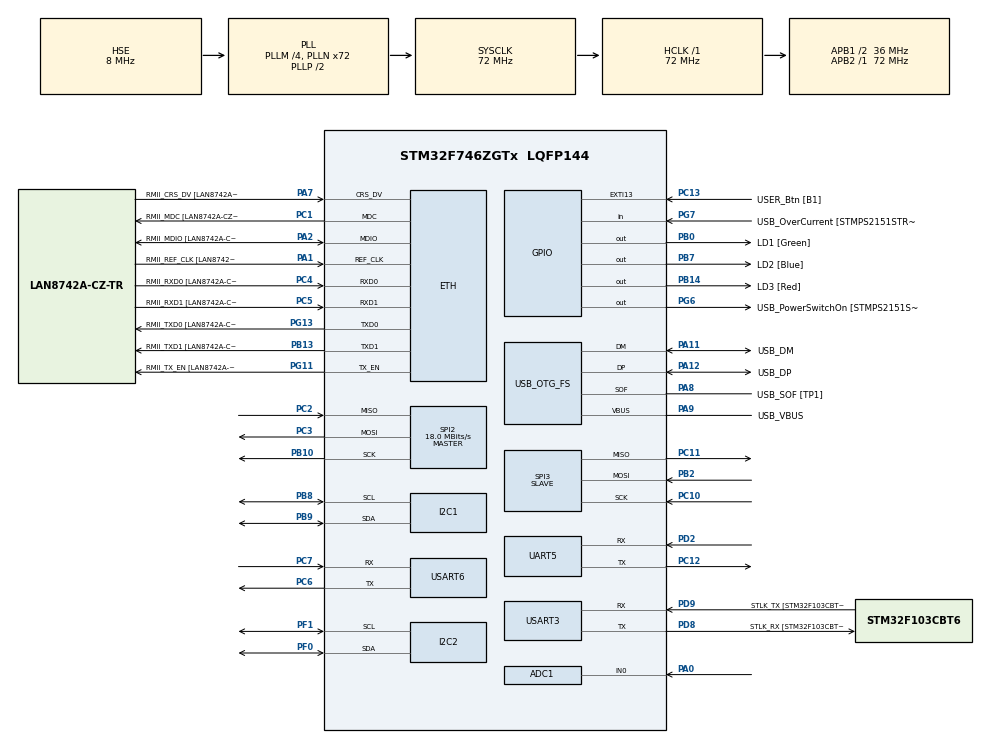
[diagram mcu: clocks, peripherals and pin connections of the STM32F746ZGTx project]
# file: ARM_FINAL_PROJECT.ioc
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ADC1.Channel-0\#ChannelRegularConversion=ADC_CHANNEL_0
ADC1.NbrOfConversionFlag=1
ADC1.Rank-0\#ChannelRegularConversion=1
ADC1.SamplingTime-0\#ChannelRegularConversion=ADC_SAMPLETIME_3CYCLES
ADC1.master=1
ETH.MediaInterface=HAL_ETH_RMII_MODE
ETH.PHY_Name=LAN8742A_PHY_ADDRESS
ETH.PHY_Value=0
ETH.PhyAddress=0
I2C1.Timing=0x00808CD2
I2C2.OwnAddress=22
I2C2.Timing=0x00808CD2
LWIP.BSP.number=1
LWIP.GATEWAY_ADDRESS=192.168.000.001
LWIP.IP_ADDRESS=192.168.000.123
LWIP.LWIP_DHCP=0
LWIP.MEM_SIZE=10*1024
LWIP.NETMASK_ADDRESS=255.255.255.000
LWIP.Version=v2.1.2_Cube
LWIP0.BSP.STBoard=false
LWIP0.BSP.api=BSP_COMPONENT_DRIVER
LWIP0.BSP.component=LAN8742
LWIP0.BSP.instance=LAN8742
LWIP0.BSP.name=Driver_PHY
LWIP0.BSP.semaphore=S_LAN8742
LWIP0.BSP.solution=LAN8742
Mcu.Family=STM32F7
Mcu.Name=STM32F746ZGTx
Mcu.Package=LQFP144
NVIC.ADC_IRQn=true\:0\:0\:false\:false\:true\:true\:true\:true
NVIC.ETH_IRQn=true\:0\:0\:false\:false\:true\:true\:true\:true
NVIC.I2C1_EV_IRQn=true\:0\:0\:false\:false\:true\:true\:true\:true
NVIC.I2C2_EV_IRQn=true\:0\:0\:false\:false\:true\:true\:true\:true
NVIC.PriorityGroup=NVIC_PRIORITYGROUP_4
NVIC.RTC_WKUP_IRQn=true\:0\:0\:false\:false\:true\:true\:true\:true
NVIC.SPI2_IRQn=true\:0\:0\:false\:false\:true\:true\:true\:true
NVIC.SPI3_IRQn=true\:0\:0\:false\:false\:true\:true\:true\:true
NVIC.TIM3_IRQn=true\:0\:0\:false\:false\:true\:true\:true\:true
NVIC.USART6_IRQn=true\:0\:0\:false\:false\:true\:true\:true\:true
PA0/WKUP.Signal=ADCx_IN0
PA1.GPIO_Label=RMII_REF_CLK [LAN8742A-CZ-TR_REFCLK0]
PA1.Mode=RMII
PA1.Signal=ETH_REF_CLK
PA10.GPIO_Label=USB_ID
PA10.Signal=USB_OTG_FS_ID
PA11.GPIO_Label=USB_DM
PA11.Mode=Device_Only
PA11.Signal=USB_OTG_FS_DM
PA12.GPIO_Label=USB_DP
PA12.Mode=Device_Only
PA12.Signal=USB_OTG_FS_DP
PA13.GPIO_Label=TMS
PA13.Mode=Serial_Wire
PA13.Signal=SYS_JTMS-SWDIO
PA14.GPIO_Label=TCK
PA14.Mode=Serial_Wire
PA14.Signal=SYS_JTCK-SWCLK
PA2.GPIO_Label=RMII_MDIO [LAN8742A-CZ-TR_MDIO]
PA2.Mode=RMII
PA2.Signal=ETH_MDIO
PA7.GPIO_Label=RMII_CRS_DV [LAN8742A-CZ-TR_CRS_DV]
PA7.Mode=RMII
PA7.Signal=ETH_CRS_DV
PA8.GPIO_Label=USB_SOF [TP1]
PA8.Mode=Activate_SOF_FS
PA8.Signal=USB_OTG_FS_SOF
PA9.GPIO_Label=USB_VBUS
PA9.Mode=Activate_VBUS
PA9.Signal=USB_OTG_FS_VBUS
PB0.GPIO_Label=LD1 [Green]
PB0.Signal=GPIO_Output
PB10.Mode=Full_Duplex_Master
PB10.Signal=SPI2_SCK
PB13.GPIO_Label=RMII_TXD1 [LAN8742A-CZ-TR_TXD1]
PB13.Mode=RMII
PB13.Signal=ETH_TXD1
PB14.GPIO_Label=LD3 [Red]
PB14.Signal=GPIO_Output
PB2.Mode=Full_Duplex_Slave
PB2.Signal=SPI3_MOSI
PB3.GPIO_Label=SW0
PB3.Signal=SYS_JTDO-SWO
PB7.GPIO_Label=LD2 [Blue]
PB7.Signal=GPIO_Output
PB8.Mode=I2C
PB8.Signal=I2C1_SCL
PB9.Mode=I2C
PB9.Signal=I2C1_SDA
PC1.GPIO_Label=RMII_MDC [LAN8742A-CZ-TR_MDC]
PC1.Mode=RMII
PC1.Signal=ETH_MDC
PC10.Mode=Full_Duplex_Slave
PC10.Signal=SPI3_SCK
PC11.Mode=Full_Duplex_Slave
PC11.Signal=SPI3_MISO
PC12.Mode=Asynchronous
PC12.Signal=UART5_TX
PC13.GPIO_Label=USER_Btn [B1]
PC13.Signal=GPXTI13
PC14/OSC32_IN.Mode=LSE-External-Oscillator
PC14/OSC32_IN.Signal=RCC_OSC32_IN
PC15/OSC32_OUT.Mode=LSE-External-Oscillator
PC15/OSC32_OUT.Signal=RCC_OSC32_OUT
PC2.Mode=Full_Duplex_Master
PC2.Signal=SPI2_MISO
PC3.Mode=Full_Duplex_Master
PC3.Signal=SPI2_MOSI
PC4.GPIO_Label=RMII_RXD0 [LAN8742A-CZ-TR_RXD0]
PC4.Mode=RMII
PC4.Signal=ETH_RXD0
PC5.GPIO_Label=RMII_RXD1 [LAN8742A-CZ-TR_RXD1]
PC5.Mode=RMII
PC5.Signal=ETH_RXD1
PC6.Mode=Asynchronous
PC6.Signal=USART6_TX
PC7.Mode=Asynchronous
PC7.Signal=USART6_RX
PD2.Mode=Asynchronous
PD2.Signal=UART5_RX
PD8.GPIO_Label=STLK_RX [STM32F103CBT6_PA3]
PD8.Mode=Asynchronous
PD8.Signal=USART3_TX
PD9.GPIO_Label=STLK_TX [STM32F103CBT6_PA2]
PD9.Mode=Asynchronous
PD9.Signal=USART3_RX
PF0.Mode=I2C
PF0.Signal=I2C2_SDA
PF1.Mode=I2C
PF1.Signal=I2C2_SCL
PG11.GPIO_Label=RMII_TX_EN [LAN8742A-CZ-TR_TXEN]
PG11.Mode=RMII
PG11.Signal=ETH_TX_EN
PG13.GPIO_Label=RMII_TXD0 [LAN8742A-CZ-TR_TXD0]
PG13.Mode=RMII
PG13.Signal=ETH_TXD0
PG6.GPIO_Label=USB_PowerSwitchOn [STMPS2151STR_EN]
PG6.Signal=GPIO_Output
PG7.GPIO_Label=USB_OverCurrent [STMPS2151STR_FAULT]
PG7.Signal=GPIO_Input
PH0/OSC_IN.GPIO_Label=MCO [STM32F103CBT6_PA8]
PH0/OSC_IN.Mode=HSE-External-Clock-Source
PH0/OSC_IN.Signal=RCC_OSC_IN
PH1/OSC_OUT.Mode=HSE-External-Clock-Source
PH1/OSC_OUT.Signal=RCC_OSC_OUT
ProjectManager.HeapSize=0x200
ProjectManager.StackSize=0x400
ProjectManager.TargetToolchain=STM32CubeIDE
RCC.48MHZClocksFreq_Value=24000000
RCC.AHBFreq_Value=72000000
RCC.APB1CLKDivider=RCC_HCLK_DIV2
RCC.APB1Freq_Value=36000000
RCC.APB1TimFreq_Value=72000000
RCC.APB2Freq_Value=72000000
RCC.APB2TimFreq_Value=72000000
RCC.CortexFreq_Value=72000000
RCC.HCLKFreq_Value=72000000
RCC.HSE_VALUE=8000000
RCC.HSI_VALUE=16000000
RCC.PLLM=4
RCC.PLLMUL=RCC_PLL_MUL9
RCC.PLLN=72
RCC.PLLQ=3
RCC.PRESCALERUSB=RCC_USBCLKSOURCE_PLL_DIV1_5
RCC.SYSCLKFreq_VALUE=72000000
RCC.SYSCLKSource=RCC_SYSCLKSOURCE_PLLCLK
RCC.SYSCLKSourceVirtual=RCC_SYSCLKSOURCE_PLLCLK
RCC.USBFreq_Value=48000000
RCC.VCOOutputFreq_Value=144000000
SH.ADCx_IN0.0=ADC1_IN0,IN0
SPI2.CalculateBaudRate=18.0 MBits/s
SPI2.DataSize=SPI_DATASIZE_8BIT
SPI2.Direction=SPI_DIRECTION_2LINES
SPI2.Mode=SPI_MODE_MASTER
SPI2.VirtualType=VM_MASTER
SPI3.DataSize=SPI_DATASIZE_8BIT
SPI3.Direction=SPI_DIRECTION_2LINES
SPI3.Mode=SPI_MODE_SLAVE
SPI3.VirtualType=VM_SLAVE
USART3.VirtualMode-Asynchronous=VM_ASYNC
USART6.VirtualMode-Asynchronous=VM_ASYNC
USB_OTG_FS.VirtualMode=Device_Only
VP_FATFS_VS_Generic.Mode=User_defined
VP_LWIP_VS_Enabled.Mode=Enabled
VP_RTC_VS_RTC_Activate.Mode=RTC_Enabled
VP_RTC_VS_RTC_Calendar.Mode=RTC_Calendar
VP_RTC_VS_RTC_WakeUp_intern.Mode=WakeUp
VP_TIM3_VS_ClockSourceINT.Mode=Internal
board=NUCLEO-F746ZG

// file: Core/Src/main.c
/* USER CODE BEGIN Header */
/**
  ******************************************************************************
  * @file           : main.c
  * @brief          : Main program body
  ******************************************************************************
  * @attention
  *
  * Copyright (c) 2022 STMicroelectronics.
  * All rights reserved.
  *
  * This software is licensed under terms that can be found in the LICENSE file
  * in the root directory of this software component.
  * If no LICENSE file comes with this software, it is provided AS-IS.
  *
  ******************************************************************************
  */
/* USER CODE END Header */
#include "main.h"
#include "fatfs.h"
#include "lwip.h"

/* USER CODE BEGIN Includes */
#include "RTG.h"
/* USER CODE END Includes */

ADC_HandleTypeDef hadc1;

I2C_HandleTypeDef hi2c1;
I2C_HandleTypeDef hi2c2;

RTC_HandleTypeDef hrtc;

SPI_HandleTypeDef hspi2;
SPI_HandleTypeDef hspi3;

TIM_HandleTypeDef htim3;

UART_HandleTypeDef huart5;
UART_HandleTypeDef huart3;
UART_HandleTypeDef huart6;

PCD_HandleTypeDef hpcd_USB_OTG_FS;

void SystemClock_Config(void);
static void MX_GPIO_Init(void);
static void MX_USART3_UART_Init(void);
static void MX_USB_OTG_FS_PCD_Init(void);
static void MX_USART6_UART_Init(void);
static void MX_I2C1_Init(void);
static void MX_I2C2_Init(void);
static void MX_SPI2_Init(void);
static void MX_SPI3_Init(void);
static void MX_ADC1_Init(void);
static void MX_TIM3_Init(void);
static void MX_UART5_Init(void);
static void MX_RTC_Init(void);

int main(void)
{

  /* MCU Configuration--------------------------------------------------------*/

  /* Reset of all peripherals, Initializes the Flash interface and the Systick. */
  HAL_Init();

  /* Configure the system clock */
  SystemClock_Config();

  /* Initialize all configured peripherals */
  MX_GPIO_Init();
  MX_USART3_UART_Init();
  MX_USB_OTG_FS_PCD_Init();
  MX_LWIP_Init();
  MX_USART6_UART_Init();
  MX_I2C1_Init();
  MX_I2C2_Init();
  MX_SPI2_Init();
  MX_SPI3_Init();
  MX_ADC1_Init();
  MX_TIM3_Init();
  MX_UART5_Init();
  MX_FATFS_Init();
  MX_RTC_Init();

  /* Infinite loop */
  while (1)
  {

    /* USER CODE BEGIN 3 */
	  rtg_main();
  }
  /* USER CODE END 3 */
}

void SystemClock_Config(void)
{
  RCC_OscInitTypeDef RCC_OscInitStruct = {0};
  RCC_ClkInitTypeDef RCC_ClkInitStruct = {0};

  /** Configure LSE Drive Capability
  */
  HAL_PWR_EnableBkUpAccess();

  /** Configure the main internal regulator output voltage
  */
  __HAL_RCC_PWR_CLK_ENABLE();
  __HAL_PWR_VOLTAGESCALING_CONFIG(PWR_REGULATOR_VOLTAGE_SCALE3);

  /** Initializes the RCC Oscillators according to the specified parameters
  * in the RCC_OscInitTypeDef structure.
  */
  RCC_OscInitStruct.OscillatorType = RCC_OSCILLATORTYPE_LSI|RCC_OSCILLATORTYPE_HSE;
  RCC_OscInitStruct.HSEState = RCC_HSE_BYPASS;
  RCC_OscInitStruct.LSIState = RCC_LSI_ON;
  RCC_OscInitStruct.PLL.PLLState = RCC_PLL_ON;
  RCC_OscInitStruct.PLL.PLLSource = RCC_PLLSOURCE_HSE;
  RCC_OscInitStruct.PLL.PLLM = 4;
  RCC_OscInitStruct.PLL.PLLN = 72;
  RCC_OscInitStruct.PLL.PLLP = RCC_PLLP_DIV2;
  RCC_OscInitStruct.PLL.PLLQ = 3;
  if (HAL_RCC_OscConfig(&RCC_OscInitStruct) != HAL_OK)
  {
    Error_Handler();
  }

  /** Initializes the CPU, AHB and APB buses clocks
  */
  RCC_ClkInitStruct.ClockType = RCC_CLOCKTYPE_HCLK|RCC_CLOCKTYPE_SYSCLK
                              |RCC_CLOCKTYPE_PCLK1|RCC_CLOCKTYPE_PCLK2;
  RCC_ClkInitStruct.SYSCLKSource = RCC_SYSCLKSOURCE_PLLCLK;
  RCC_ClkInitStruct.AHBCLKDivider = RCC_SYSCLK_DIV1;
  RCC_ClkInitStruct.APB1CLKDivider = RCC_HCLK_DIV2;
  RCC_ClkInitStruct.APB2CLKDivider = RCC_HCLK_DIV1;

  if (HAL_RCC_ClockConfig(&RCC_ClkInitStruct, FLASH_LATENCY_2) != HAL_OK)
  {
    Error_Handler();
  }
}

static void MX_ADC1_Init(void)
{

  ADC_ChannelConfTypeDef sConfig = {0};

  /** Configure the global features of the ADC (Clock, Resolution, Data Alignment and number of conversion)
  */
  hadc1.Instance = ADC1;
  hadc1.Init.ClockPrescaler = ADC_CLOCK_SYNC_PCLK_DIV2;
  hadc1.Init.Resolution = ADC_RESOLUTION_12B;
  hadc1.Init.ScanConvMode = ADC_SCAN_DISABLE;
  hadc1.Init.ContinuousConvMode = DISABLE;
  hadc1.Init.DiscontinuousConvMode = DISABLE;
  hadc1.Init.ExternalTrigConvEdge = ADC_EXTERNALTRIGCONVEDGE_NONE;
  hadc1.Init.ExternalTrigConv = ADC_SOFTWARE_START;
  hadc1.Init.DataAlign = ADC_DATAALIGN_RIGHT;
  hadc1.Init.NbrOfConversion = 1;
  hadc1.Init.DMAContinuousRequests = DISABLE;
  hadc1.Init.EOCSelection = ADC_EOC_SINGLE_CONV;
  if (HAL_ADC_Init(&hadc1) != HAL_OK)
  {
    Error_Handler();
  }

  /** Configure for the selected ADC regular channel its corresponding rank in the sequencer and its sample time.
  */
  sConfig.Channel = ADC_CHANNEL_0;
  sConfig.Rank = ADC_REGULAR_RANK_1;
  sConfig.SamplingTime = ADC_SAMPLETIME_3CYCLES;
  if (HAL_ADC_ConfigChannel(&hadc1, &sConfig) != HAL_OK)
  {
    Error_Handler();
  }

}

static void MX_I2C1_Init(void)
{

  hi2c1.Instance = I2C1;
  hi2c1.Init.Timing = 0x00808CD2;
  hi2c1.Init.OwnAddress1 = 0;
  hi2c1.Init.AddressingMode = I2C_ADDRESSINGMODE_7BIT;
  hi2c1.Init.DualAddressMode = I2C_DUALADDRESS_DISABLE;
  hi2c1.Init.OwnAddress2 = 0;
  hi2c1.Init.OwnAddress2Masks = I2C_OA2_NOMASK;
  hi2c1.Init.GeneralCallMode = I2C_GENERALCALL_DISABLE;
  hi2c1.Init.NoStretchMode = I2C_NOSTRETCH_DISABLE;
  if (HAL_I2C_Init(&hi2c1) != HAL_OK)
  {
    Error_Handler();
  }

  /** Configure Analogue filter
  */
  if (HAL_I2CEx_ConfigAnalogFilter(&hi2c1, I2C_ANALOGFILTER_ENABLE) != HAL_OK)
  {
    Error_Handler();
  }

  /** Configure Digital filter
  */
  if (HAL_I2CEx_ConfigDigitalFilter(&hi2c1, 0) != HAL_OK)
  {
    Error_Handler();
  }

}

static void MX_I2C2_Init(void)
{

  hi2c2.Instance = I2C2;
  hi2c2.Init.Timing = 0x00808CD2;
  hi2c2.Init.OwnAddress1 = 44;
  hi2c2.Init.AddressingMode = I2C_ADDRESSINGMODE_7BIT;
  hi2c2.Init.DualAddressMode = I2C_DUALADDRESS_DISABLE;
  hi2c2.Init.OwnAddress2 = 0;
  hi2c2.Init.OwnAddress2Masks = I2C_OA2_NOMASK;
  hi2c2.Init.GeneralCallMode = I2C_GENERALCALL_DISABLE;
  hi2c2.Init.NoStretchMode = I2C_NOSTRETCH_DISABLE;
  if (HAL_I2C_Init(&hi2c2) != HAL_OK)
  {
    Error_Handler();
  }

  /** Configure Analogue filter
  */
  if (HAL_I2CEx_ConfigAnalogFilter(&hi2c2, I2C_ANALOGFILTER_ENABLE) != HAL_OK)
  {
    Error_Handler();
  }

  /** Configure Digital filter
  */
  if (HAL_I2CEx_ConfigDigitalFilter(&hi2c2, 0) != HAL_OK)
  {
    Error_Handler();
  }

}

static void MX_RTC_Init(void)
{

  RTC_TimeTypeDef sTime = {0};
  RTC_DateTypeDef sDate = {0};

  /** Initialize RTC Only
  */
  hrtc.Instance = RTC;
  hrtc.Init.HourFormat = RTC_HOURFORMAT_24;
  hrtc.Init.AsynchPrediv = 127;
  hrtc.Init.SynchPrediv = 255;
  hrtc.Init.OutPut = RTC_OUTPUT_DISABLE;
  hrtc.Init.OutPutPolarity = RTC_OUTPUT_POLARITY_HIGH;
  hrtc.Init.OutPutType = RTC_OUTPUT_TYPE_OPENDRAIN;
  if (HAL_RTC_Init(&hrtc) != HAL_OK)
  {
    Error_Handler();
  }

  /** Initialize RTC and set the Time and Date
  */
  sTime.Hours = 0x0;
  sTime.Minutes = 0x0;
  sTime.Seconds = 0x0;
  sTime.DayLightSaving = RTC_DAYLIGHTSAVING_NONE;
  sTime.StoreOperation = RTC_STOREOPERATION_RESET;
  if (HAL_RTC_SetTime(&hrtc, &sTime, RTC_FORMAT_BCD) != HAL_OK)
  {
    Error_Handler();
  }
  sDate.WeekDay = RTC_WEEKDAY_MONDAY;
  sDate.Month = RTC_MONTH_JANUARY;
  sDate.Date = 0x1;
  sDate.Year = 0x0;

  if (HAL_RTC_SetDate(&hrtc, &sDate, RTC_FORMAT_BCD) != HAL_OK)
  {
    Error_Handler();
  }

  /** Enable the WakeUp
  */
  if (HAL_RTCEx_SetWakeUpTimer_IT(&hrtc, 0, RTC_WAKEUPCLOCK_RTCCLK_DIV16) != HAL_OK)
  {
    Error_Handler();
  }

}

static void MX_SPI2_Init(void)
{

  /* SPI2 parameter configuration*/
  hspi2.Instance = SPI2;
  hspi2.Init.Mode = SPI_MODE_MASTER;
  hspi2.Init.Direction = SPI_DIRECTION_2LINES;
  hspi2.Init.DataSize = SPI_DATASIZE_8BIT;
  hspi2.Init.CLKPolarity = SPI_POLARITY_LOW;
  hspi2.Init.CLKPhase = SPI_PHASE_1EDGE;
  hspi2.Init.NSS = SPI_NSS_SOFT;
  hspi2.Init.BaudRatePrescaler = SPI_BAUDRATEPRESCALER_2;
  hspi2.Init.FirstBit = SPI_FIRSTBIT_MSB;
  hspi2.Init.TIMode = SPI_TIMODE_DISABLE;
  hspi2.Init.CRCCalculation = SPI_CRCCALCULATION_DISABLE;
  hspi2.Init.CRCPolynomial = 7;
  hspi2.Init.CRCLength = SPI_CRC_LENGTH_DATASIZE;
  hspi2.Init.NSSPMode = SPI_NSS_PULSE_ENABLE;
  if (HAL_SPI_Init(&hspi2) != HAL_OK)
  {
    Error_Handler();
  }

}

static void MX_SPI3_Init(void)
{

  /* SPI3 parameter configuration*/
  hspi3.Instance = SPI3;
  hspi3.Init.Mode = SPI_MODE_SLAVE;
  hspi3.Init.Direction = SPI_DIRECTION_2LINES;
  hspi3.Init.DataSize = SPI_DATASIZE_8BIT;
  hspi3.Init.CLKPolarity = SPI_POLARITY_LOW;
  hspi3.Init.CLKPhase = SPI_PHASE_1EDGE;
  hspi3.Init.NSS = SPI_NSS_SOFT;
  hspi3.Init.FirstBit = SPI_FIRSTBIT_MSB;
  hspi3.Init.TIMode = SPI_TIMODE_DISABLE;
  hspi3.Init.CRCCalculation = SPI_CRCCALCULATION_DISABLE;
  hspi3.Init.CRCPolynomial = 7;
  hspi3.Init.CRCLength = SPI_CRC_LENGTH_DATASIZE;
  hspi3.Init.NSSPMode = SPI_NSS_PULSE_DISABLE;
  if (HAL_SPI_Init(&hspi3) != HAL_OK)
  {
    Error_Handler();
  }

}

static void MX_TIM3_Init(void)
{

  TIM_ClockConfigTypeDef sClockSourceConfig = {0};
  TIM_MasterConfigTypeDef sMasterConfig = {0};

  htim3.Instance = TIM3;
  htim3.Init.Prescaler = 0;
  htim3.Init.CounterMode = TIM_COUNTERMODE_UP;
  htim3.Init.Period = 65535;
  htim3.Init.ClockDivision = TIM_CLOCKDIVISION_DIV1;
  htim3.Init.AutoReloadPreload = TIM_AUTORELOAD_PRELOAD_DISABLE;
  if (HAL_TIM_Base_Init(&htim3) != HAL_OK)
  {
    Error_Handler();
  }
  sClockSourceConfig.ClockSource = TIM_CLOCKSOURCE_INTERNAL;
  if (HAL_TIM_ConfigClockSource(&htim3, &sClockSourceConfig) != HAL_OK)
  {
    Error_Handler();
  }
  sMasterConfig.MasterOutputTrigger = TIM_TRGO_RESET;
  sMasterConfig.MasterSlaveMode = TIM_MASTERSLAVEMODE_DISABLE;
  if (HAL_TIMEx_MasterConfigSynchronization(&htim3, &sMasterConfig) != HAL_OK)
  {
    Error_Handler();
  }

}

static void MX_UART5_Init(void)
{

  huart5.Instance = UART5;
  huart5.Init.BaudRate = 115200;
  huart5.Init.WordLength = UART_WORDLENGTH_8B;
  huart5.Init.StopBits = UART_STOPBITS_1;
  huart5.Init.Parity = UART_PARITY_NONE;
  huart5.Init.Mode = UART_MODE_TX_RX;
  huart5.Init.HwFlowCtl = UART_HWCONTROL_NONE;
  huart5.Init.OverSampling = UART_OVERSAMPLING_16;
  huart5.Init.OneBitSampling = UART_ONE_BIT_SAMPLE_DISABLE;
  huart5.AdvancedInit.AdvFeatureInit = UART_ADVFEATURE_NO_INIT;
  if (HAL_UART_Init(&huart5) != HAL_OK)
  {
    Error_Handler();
  }

}

static void MX_USART3_UART_Init(void)
{

  huart3.Instance = USART3;
  huart3.Init.BaudRate = 115200;
  huart3.Init.WordLength = UART_WORDLENGTH_8B;
  huart3.Init.StopBits = UART_STOPBITS_1;
  huart3.Init.Parity = UART_PARITY_NONE;
  huart3.Init.Mode = UART_MODE_TX_RX;
  huart3.Init.HwFlowCtl = UART_HWCONTROL_NONE;
  huart3.Init.OverSampling = UART_OVERSAMPLING_16;
  huart3.Init.OneBitSampling = UART_ONE_BIT_SAMPLE_DISABLE;
  huart3.AdvancedInit.AdvFeatureInit = UART_ADVFEATURE_NO_INIT;
  if (HAL_UART_Init(&huart3) != HAL_OK)
  {
    Error_Handler();
  }

}

static void MX_USART6_UART_Init(void)
{

  huart6.Instance = USART6;
  huart6.Init.BaudRate = 115200;
  huart6.Init.WordLength = UART_WORDLENGTH_8B;
  huart6.Init.StopBits = UART_STOPBITS_1;
  huart6.Init.Parity = UART_PARITY_NONE;
  huart6.Init.Mode = UART_MODE_TX_RX;
  huart6.Init.HwFlowCtl = UART_HWCONTROL_NONE;
  huart6.Init.OverSampling = UART_OVERSAMPLING_16;
  huart6.Init.OneBitSampling = UART_ONE_BIT_SAMPLE_DISABLE;
  huart6.AdvancedInit.AdvFeatureInit = UART_ADVFEATURE_NO_INIT;
  if (HAL_UART_Init(&huart6) != HAL_OK)
  {
    Error_Handler();
  }

}

static void MX_USB_OTG_FS_PCD_Init(void)
{

  hpcd_USB_OTG_FS.Instance = USB_OTG_FS;
  hpcd_USB_OTG_FS.Init.dev_endpoints = 6;
  hpcd_USB_OTG_FS.Init.speed = PCD_SPEED_FULL;
  hpcd_USB_OTG_FS.Init.dma_enable = DISABLE;
  hpcd_USB_OTG_FS.Init.phy_itface = PCD_PHY_EMBEDDED;
  hpcd_USB_OTG_FS.Init.Sof_enable = ENABLE;
  hpcd_USB_OTG_FS.Init.low_power_enable = DISABLE;
  hpcd_USB_OTG_FS.Init.lpm_enable = DISABLE;
  hpcd_USB_OTG_FS.Init.vbus_sensing_enable = ENABLE;
  hpcd_USB_OTG_FS.Init.use_dedicated_ep1 = DISABLE;
  if (HAL_PCD_Init(&hpcd_USB_OTG_FS) != HAL_OK)
  {
    Error_Handler();
  }

}

static void MX_GPIO_Init(void)
{
  GPIO_InitTypeDef GPIO_InitStruct = {0};

  /* GPIO Ports Clock Enable */
  __HAL_RCC_GPIOC_CLK_ENABLE();
  __HAL_RCC_GPIOF_CLK_ENABLE();
  __HAL_RCC_GPIOH_CLK_ENABLE();
  __HAL_RCC_GPIOA_CLK_ENABLE();
  __HAL_RCC_GPIOB_CLK_ENABLE();
  __HAL_RCC_GPIOD_CLK_ENABLE();
  __HAL_RCC_GPIOG_CLK_ENABLE();

  /*Configure GPIO pin Output Level */
  HAL_GPIO_WritePin(GPIOB, LD1_Pin|LD3_Pin|LD2_Pin, GPIO_PIN_RESET);

  /*Configure GPIO pin Output Level */
  HAL_GPIO_WritePin(USB_PowerSwitchOn_GPIO_Port, USB_PowerSwitchOn_Pin, GPIO_PIN_RESET);

  /*Configure GPIO pin : USER_Btn_Pin */
  GPIO_InitStruct.Pin = USER_Btn_Pin;
  GPIO_InitStruct.Mode = GPIO_MODE_IT_RISING;
  GPIO_InitStruct.Pull = GPIO_NOPULL;
  HAL_GPIO_Init(USER_Btn_GPIO_Port, &GPIO_InitStruct);

  /*Configure GPIO pins : LD1_Pin LD3_Pin LD2_Pin */
  GPIO_InitStruct.Pin = LD1_Pin|LD3_Pin|LD2_Pin;
  GPIO_InitStruct.Mode = GPIO_MODE_OUTPUT_PP;
  GPIO_InitStruct.Pull = GPIO_NOPULL;
  GPIO_InitStruct.Speed = GPIO_SPEED_FREQ_LOW;
  HAL_GPIO_Init(GPIOB, &GPIO_InitStruct);

  /*Configure GPIO pin : USB_PowerSwitchOn_Pin */
  GPIO_InitStruct.Pin = USB_PowerSwitchOn_Pin;
  GPIO_InitStruct.Mode = GPIO_MODE_OUTPUT_PP;
  GPIO_InitStruct.Pull = GPIO_NOPULL;
  GPIO_InitStruct.Speed = GPIO_SPEED_FREQ_LOW;
  HAL_GPIO_Init(USB_PowerSwitchOn_GPIO_Port, &GPIO_InitStruct);

  /*Configure GPIO pin : USB_OverCurrent_Pin */
  GPIO_InitStruct.Pin = USB_OverCurrent_Pin;
  GPIO_InitStruct.Mode = GPIO_MODE_INPUT;
  GPIO_InitStruct.Pull = GPIO_NOPULL;
  HAL_GPIO_Init(USB_OverCurrent_GPIO_Port, &GPIO_InitStruct);

}

void Error_Handler(void)
{
  __disable_irq();
  while (1)
  {
  }
}
